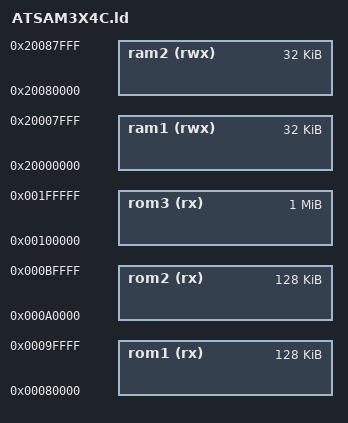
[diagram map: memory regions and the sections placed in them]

MEMORY
{
  rom1 (rx) : ORIGIN = 0x00080000, LENGTH = 0x00020000
  rom2 (rx) : ORIGIN = 0xA0000, LENGTH = 0x00020000
  rom3 (rx) : ORIGIN = 0x00100000, LENGTH = 0x00100000
  ram1 (rwx) : ORIGIN = 0x20000000, LENGTH = 0x00008000
  ram2 (rwx) : ORIGIN = 0x20080000, LENGTH = 0x00008000
}

